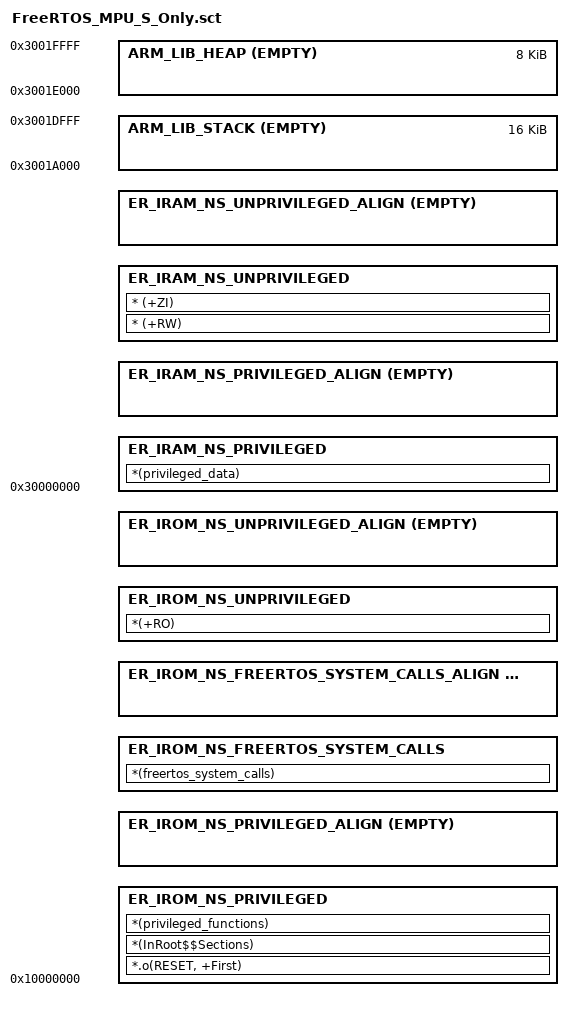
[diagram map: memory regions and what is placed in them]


/*--------------------- Flash Configuration ----------------------------------*/
#define CM55M_S_APP_ROM_BASE     0x10000000
#define CM55M_S_APP_ROM_SIZE     0x00020000

/*--------------------- Embedded RAM Configuration ---------------------------*/
#define CM55M_S_APP_DATA_BASE     0x30000000
#define CM55M_S_APP_DATA_SIZE     0x00020000

/*--------------------- Stack / Heap Configuration ---------------------------*/
#define __STACK_S_SIZE    0x00004000
#define __HEAP_S_SIZE     0x00002000
#define CM55M_S_APP_DATASECT_SIZE  (CM55M_S_APP_DATA_SIZE - __STACK_S_SIZE - __HEAP_S_SIZE)
#define __STACK_LIMIT   (CM55M_S_APP_DATA_BASE + CM55M_S_APP_DATASECT_SIZE)
#define __STACK_BASE    (CM55M_S_APP_DATA_BASE + CM55M_S_APP_DATASECT_SIZE + __STACK_S_SIZE)
#define __HEAP_BASE     (CM55M_S_APP_DATA_BASE + CM55M_S_APP_DATASECT_SIZE + __STACK_S_SIZE)
#define __HEAP_LIMIT    (CM55M_S_APP_DATA_BASE + CM55M_S_APP_DATASECT_SIZE + __STACK_S_SIZE + __HEAP_S_SIZE)

LR_ROM1 CM55M_S_APP_ROM_BASE CM55M_S_APP_ROM_SIZE
{
    ER_IROM_NS_PRIVILEGED +0 ALIGN 32
    {
        *.o(RESET, +First)
        *(InRoot$$Sections)
        *(privileged_functions)
    }

    ER_IROM_NS_PRIVILEGED_ALIGN +0 ALIGN 32 EMPTY 0x0
    {
    }

    ER_IROM_NS_FREERTOS_SYSTEM_CALLS +0 ALIGN 32
    {
        *(freertos_system_calls)
    }

    ER_IROM_NS_FREERTOS_SYSTEM_CALLS_ALIGN +0 ALIGN 32 EMPTY 0x0
    {
    }

    ER_IROM_NS_UNPRIVILEGED +0 ALIGN 32
    {
        *(+RO)
    }

    ER_IROM_NS_UNPRIVILEGED_ALIGN +0 ALIGN 32 EMPTY 0x0
    {
    }
}

LR_ROM2 CM55M_S_APP_DATA_BASE CM55M_S_APP_DATA_SIZE
{
    ER_IRAM_NS_PRIVILEGED +0 ALIGN 32
    {
        *(privileged_data)
    }

    ER_IRAM_NS_PRIVILEGED_ALIGN +0 ALIGN 32 EMPTY 0x0
    {
    }

    ER_IRAM_NS_UNPRIVILEGED +0 ALIGN 32
    {
	   * (+RW)
	   * (+ZI)
    }

    ER_IRAM_NS_UNPRIVILEGED_ALIGN +0 ALIGN 32 EMPTY 0x0
    {
    }
    
    ARM_LIB_STACK __STACK_BASE ALIGN 8 EMPTY -__STACK_S_SIZE {
  	}
  
  	ARM_LIB_HEAP  __HEAP_BASE ALIGN 8 EMPTY __HEAP_S_SIZE  {
  	}
}
